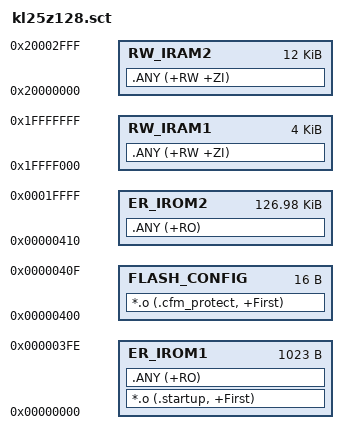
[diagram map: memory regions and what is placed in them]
/* Scatter file for KL25Z128 */


; load region size_region
LR_IROM1 0x00000000 0x000003FF  
{    
	; Interrupt vectors
	ER_IROM1 0x00000000 0x000003FF  
	{  
		*.o (.startup, +First)
		.ANY (+RO)
  	}
}

; load region size_region
LR_IROM2 0x00000400 0x00000010  
{     	
  	; Flash configuration
  	FLASH_CONFIG 0x00000400 0x00000010  
	{  
		*.o (.cfm_protect, +First)
  	}
}

; load region size_region
LR_IROM3 0x00000410 0x0001FBF0  
{    	
  	; Internal ROM
  	ER_IROM2 0x00000410 0x0001FBF0  
	{  
		.ANY (+RO)
  	}
  	
  	; RW data
  	RW_IRAM1 0x1FFFF000 0x00001000  
  	{  
		.ANY (+RW +ZI)
  	}
  	RW_IRAM2 0x20000000 0x00003000  
  	{
		.ANY (+RW +ZI)
  	}
}

	  
